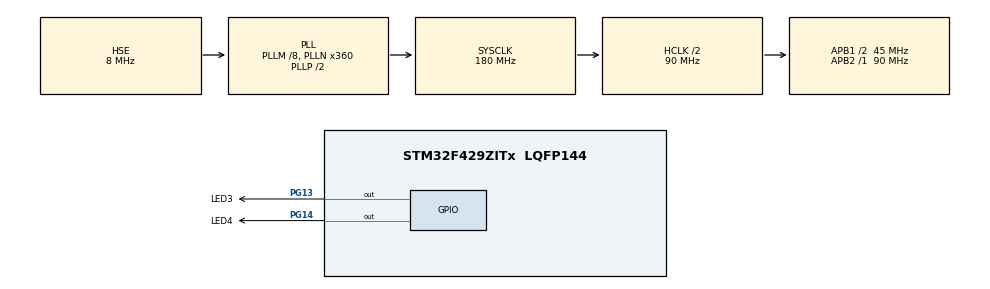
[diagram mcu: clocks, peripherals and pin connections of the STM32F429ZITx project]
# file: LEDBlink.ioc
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Mcu.Family=STM32F4
Mcu.Name=STM32F429ZITx
Mcu.Package=LQFP144
NVIC.PriorityGroup=NVIC_PRIORITYGROUP_4
NVIC.TIM2_IRQn=true\:0\:0\:false\:false\:true\:true\:true\:true
NVIC.TIM3_IRQn=true\:0\:0\:false\:false\:true\:true\:true\:true
PA13.Mode=Serial_Wire
PA13.Signal=SYS_JTMS-SWDIO
PA14.Mode=Serial_Wire
PA14.Signal=SYS_JTCK-SWCLK
PG13.GPIO_Label=LED3
PG13.GPIO_Speed=GPIO_SPEED_FREQ_HIGH
PG13.Signal=GPIO_Output
PG14.GPIO_Label=LED4
PG14.GPIO_Speed=GPIO_SPEED_FREQ_HIGH
PG14.Signal=GPIO_Output
PH0/OSC_IN.Mode=HSE-External-Oscillator
PH0/OSC_IN.Signal=RCC_OSC_IN
PH1/OSC_OUT.Mode=HSE-External-Oscillator
PH1/OSC_OUT.Signal=RCC_OSC_OUT
ProjectManager.HeapSize=0x200
ProjectManager.StackSize=0x400
ProjectManager.TargetToolchain=STM32CubeIDE
RCC.48MHZClocksFreq_Value=90000000
RCC.AHBCLKDivider=RCC_SYSCLK_DIV2
RCC.AHBFreq_Value=90000000
RCC.APB1CLKDivider=RCC_HCLK_DIV2
RCC.APB1Freq_Value=45000000
RCC.APB1TimFreq_Value=90000000
RCC.APB2Freq_Value=90000000
RCC.APB2TimFreq_Value=90000000
RCC.CortexFreq_Value=90000000
RCC.HCLKFreq_Value=90000000
RCC.HSE_VALUE=8000000
RCC.HSI_VALUE=16000000
RCC.LSE_VALUE=32768
RCC.PLLM=8
RCC.PLLN=360
RCC.PLLSourceVirtual=RCC_PLLSOURCE_HSE
RCC.SYSCLKFreq_VALUE=180000000
RCC.SYSCLKSource=RCC_SYSCLKSOURCE_PLLCLK
RCC.VCOOutputFreq_Value=360000000
TIM2.AutoReloadPreload=TIM_AUTORELOAD_PRELOAD_ENABLE
TIM2.Period=9999
TIM2.Prescaler=18000
TIM3.AutoReloadPreload=TIM_AUTORELOAD_PRELOAD_ENABLE
TIM3.Period=7499
TIM3.Prescaler=18000
VP_TIM2_VS_ClockSourceINT.Mode=Internal
VP_TIM3_VS_ClockSourceINT.Mode=Internal
board=custom

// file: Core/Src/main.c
/* USER CODE BEGIN Header */
/**
  ******************************************************************************
  * @file           : main.c
  * @brief          : Main program body
  ******************************************************************************
  * @attention
  *
  * Copyright (c) 2022 STMicroelectronics.
  * All rights reserved.
  *
  * This software is licensed under terms that can be found in the LICENSE file
  * in the root directory of this software component.
  * If no LICENSE file comes with this software, it is provided AS-IS.
  *
  ******************************************************************************
  */
/* USER CODE END Header */
#include "main.h"

TIM_HandleTypeDef htim2;
TIM_HandleTypeDef htim3;

void SystemClock_Config(void);
static void MX_GPIO_Init(void);
static void MX_TIM2_Init(void);
static void MX_TIM3_Init(void);

int main(void)
{

  /* MCU Configuration--------------------------------------------------------*/

  /* Reset of all peripherals, Initializes the Flash interface and the Systick. */
  HAL_Init();

  /* Configure the system clock */
  SystemClock_Config();

  /* Initialize all configured peripherals */
  MX_GPIO_Init();
  MX_TIM2_Init();
  MX_TIM3_Init();
  /* USER CODE BEGIN 2 */
  HAL_TIM_Base_Start_IT(&htim2);
  HAL_TIM_Base_Start_IT(&htim3);

  /* USER CODE END 2 */

  /* Infinite loop */
  while (1)
  {

  }
}

void SystemClock_Config(void)
{
  RCC_OscInitTypeDef RCC_OscInitStruct = {0};
  RCC_ClkInitTypeDef RCC_ClkInitStruct = {0};

  /** Configure the main internal regulator output voltage
  */
  __HAL_RCC_PWR_CLK_ENABLE();
  __HAL_PWR_VOLTAGESCALING_CONFIG(PWR_REGULATOR_VOLTAGE_SCALE3);

  /** Initializes the RCC Oscillators according to the specified parameters
  * in the RCC_OscInitTypeDef structure.
  */
  RCC_OscInitStruct.OscillatorType = RCC_OSCILLATORTYPE_HSE;
  RCC_OscInitStruct.HSEState = RCC_HSE_ON;
  RCC_OscInitStruct.PLL.PLLState = RCC_PLL_ON;
  RCC_OscInitStruct.PLL.PLLSource = RCC_PLLSOURCE_HSE;
  RCC_OscInitStruct.PLL.PLLM = 8;
  RCC_OscInitStruct.PLL.PLLN = 360;
  RCC_OscInitStruct.PLL.PLLP = RCC_PLLP_DIV2;
  RCC_OscInitStruct.PLL.PLLQ = 4;
  if (HAL_RCC_OscConfig(&RCC_OscInitStruct) != HAL_OK)
  {
    Error_Handler();
  }

  /** Activate the Over-Drive mode
  */
  if (HAL_PWREx_EnableOverDrive() != HAL_OK)
  {
    Error_Handler();
  }

  /** Initializes the CPU, AHB and APB buses clocks
  */
  RCC_ClkInitStruct.ClockType = RCC_CLOCKTYPE_HCLK|RCC_CLOCKTYPE_SYSCLK
                              |RCC_CLOCKTYPE_PCLK1|RCC_CLOCKTYPE_PCLK2;
  RCC_ClkInitStruct.SYSCLKSource = RCC_SYSCLKSOURCE_PLLCLK;
  RCC_ClkInitStruct.AHBCLKDivider = RCC_SYSCLK_DIV2;
  RCC_ClkInitStruct.APB1CLKDivider = RCC_HCLK_DIV2;
  RCC_ClkInitStruct.APB2CLKDivider = RCC_HCLK_DIV1;

  if (HAL_RCC_ClockConfig(&RCC_ClkInitStruct, FLASH_LATENCY_2) != HAL_OK)
  {
    Error_Handler();
  }
}

static void MX_TIM2_Init(void)
{

  TIM_ClockConfigTypeDef sClockSourceConfig = {0};
  TIM_MasterConfigTypeDef sMasterConfig = {0};

  htim2.Instance = TIM2;
  htim2.Init.Prescaler = 18000;
  htim2.Init.CounterMode = TIM_COUNTERMODE_UP;
  htim2.Init.Period = 9999;
  htim2.Init.ClockDivision = TIM_CLOCKDIVISION_DIV1;
  htim2.Init.AutoReloadPreload = TIM_AUTORELOAD_PRELOAD_ENABLE;
  if (HAL_TIM_Base_Init(&htim2) != HAL_OK)
  {
    Error_Handler();
  }
  sClockSourceConfig.ClockSource = TIM_CLOCKSOURCE_INTERNAL;
  if (HAL_TIM_ConfigClockSource(&htim2, &sClockSourceConfig) != HAL_OK)
  {
    Error_Handler();
  }
  sMasterConfig.MasterOutputTrigger = TIM_TRGO_RESET;
  sMasterConfig.MasterSlaveMode = TIM_MASTERSLAVEMODE_DISABLE;
  if (HAL_TIMEx_MasterConfigSynchronization(&htim2, &sMasterConfig) != HAL_OK)
  {
    Error_Handler();
  }

}

static void MX_TIM3_Init(void)
{

  TIM_ClockConfigTypeDef sClockSourceConfig = {0};
  TIM_MasterConfigTypeDef sMasterConfig = {0};

  htim3.Instance = TIM3;
  htim3.Init.Prescaler = 18000;
  htim3.Init.CounterMode = TIM_COUNTERMODE_UP;
  htim3.Init.Period = 7499;
  htim3.Init.ClockDivision = TIM_CLOCKDIVISION_DIV1;
  htim3.Init.AutoReloadPreload = TIM_AUTORELOAD_PRELOAD_ENABLE;
  if (HAL_TIM_Base_Init(&htim3) != HAL_OK)
  {
    Error_Handler();
  }
  sClockSourceConfig.ClockSource = TIM_CLOCKSOURCE_INTERNAL;
  if (HAL_TIM_ConfigClockSource(&htim3, &sClockSourceConfig) != HAL_OK)
  {
    Error_Handler();
  }
  sMasterConfig.MasterOutputTrigger = TIM_TRGO_RESET;
  sMasterConfig.MasterSlaveMode = TIM_MASTERSLAVEMODE_DISABLE;
  if (HAL_TIMEx_MasterConfigSynchronization(&htim3, &sMasterConfig) != HAL_OK)
  {
    Error_Handler();
  }

}

static void MX_GPIO_Init(void)
{
  GPIO_InitTypeDef GPIO_InitStruct = {0};

  /* GPIO Ports Clock Enable */
  __HAL_RCC_GPIOH_CLK_ENABLE();
  __HAL_RCC_GPIOA_CLK_ENABLE();
  __HAL_RCC_GPIOG_CLK_ENABLE();

  /*Configure GPIO pin Output Level */
  HAL_GPIO_WritePin(GPIOG, LED3_Pin|LED4_Pin, GPIO_PIN_RESET);

  /*Configure GPIO pins : LED3_Pin LED4_Pin */
  GPIO_InitStruct.Pin = LED3_Pin|LED4_Pin;
  GPIO_InitStruct.Mode = GPIO_MODE_OUTPUT_PP;
  GPIO_InitStruct.Pull = GPIO_NOPULL;
  GPIO_InitStruct.Speed = GPIO_SPEED_FREQ_HIGH;
  HAL_GPIO_Init(GPIOG, &GPIO_InitStruct);

}

/* USER CODE BEGIN 4 */
void HAL_TIM_PeriodElapsedCallback(TIM_HandleTypeDef *htim)
{
	if(htim->Instance ==  TIM2)
	{
		HAL_GPIO_TogglePin(GPIOG,GPIO_PIN_13);
	}
	if(htim->Instance ==  TIM3)
	{
		HAL_GPIO_TogglePin(GPIOG,GPIO_PIN_14);
	}
}

/* USER CODE END 4 */

void Error_Handler(void)
{
  __disable_irq();
  while (1)
  {
  }
}
